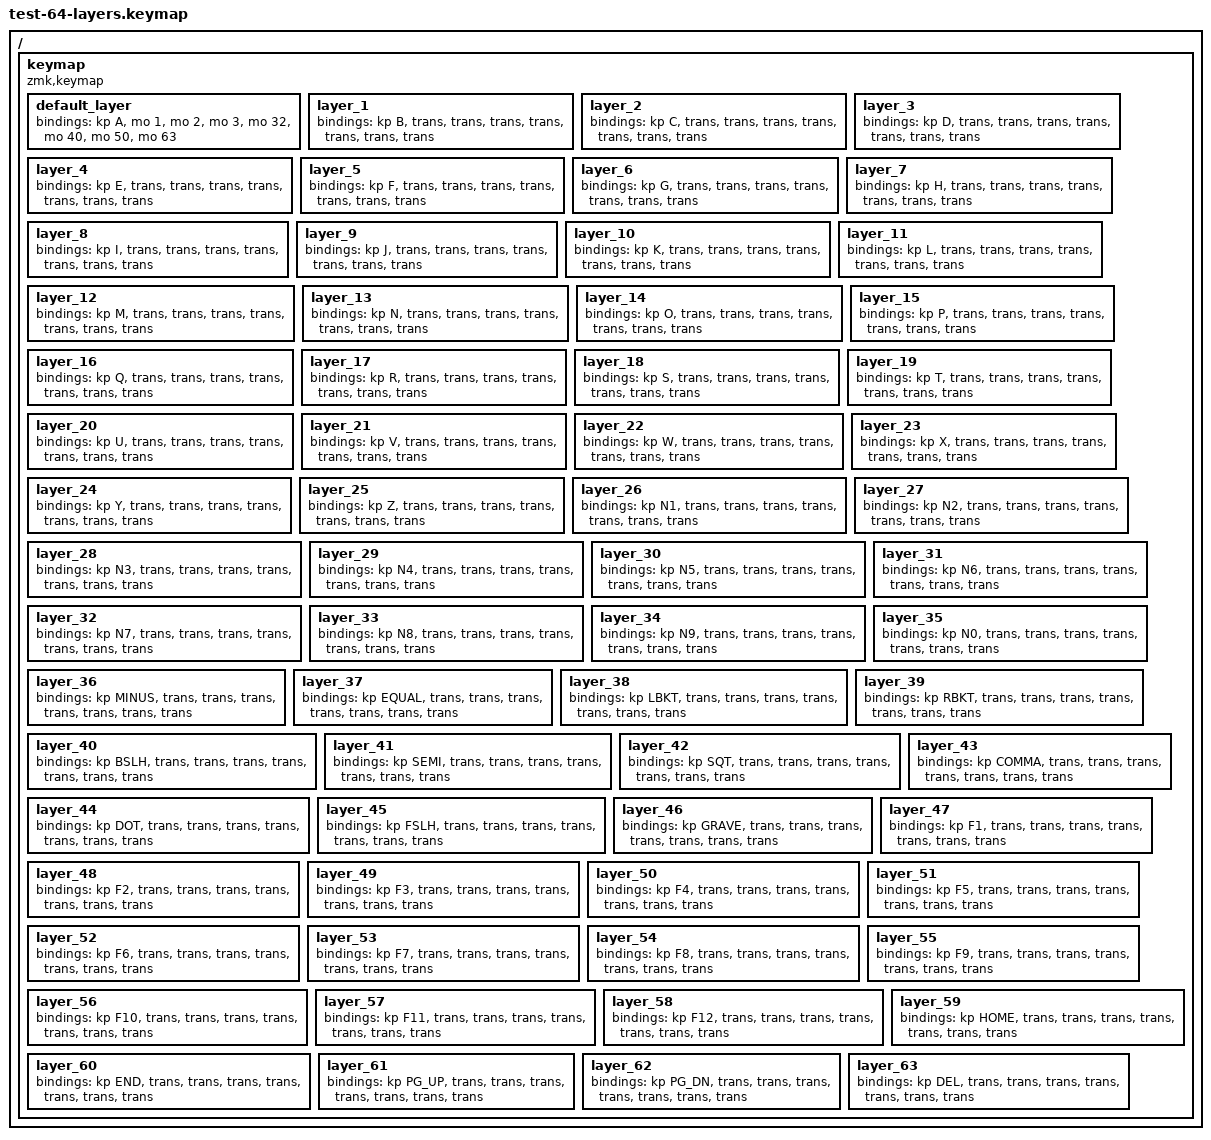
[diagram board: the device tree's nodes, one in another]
/*
 * Test keymap with 64 layers to verify 64-layer support
 * This demonstrates that layers 0-63 can be used
 */

#include <behaviors.dtsi>
#include <dt-bindings/zmk/keys.h>
#include <dt-bindings/zmk/bt.h>

/ {
    keymap {
        compatible = "zmk,keymap";

        // Layer 0-31 (originally supported)
        default_layer { bindings = <&kp A &mo 1 &mo 2 &mo 3 &mo 32 &mo 40 &mo 50 &mo 63>; };
        layer_1 { bindings = <&kp B &trans &trans &trans &trans &trans &trans &trans>; };
        layer_2 { bindings = <&kp C &trans &trans &trans &trans &trans &trans &trans>; };
        layer_3 { bindings = <&kp D &trans &trans &trans &trans &trans &trans &trans>; };
        layer_4 { bindings = <&kp E &trans &trans &trans &trans &trans &trans &trans>; };
        layer_5 { bindings = <&kp F &trans &trans &trans &trans &trans &trans &trans>; };
        layer_6 { bindings = <&kp G &trans &trans &trans &trans &trans &trans &trans>; };
        layer_7 { bindings = <&kp H &trans &trans &trans &trans &trans &trans &trans>; };
        layer_8 { bindings = <&kp I &trans &trans &trans &trans &trans &trans &trans>; };
        layer_9 { bindings = <&kp J &trans &trans &trans &trans &trans &trans &trans>; };
        layer_10 { bindings = <&kp K &trans &trans &trans &trans &trans &trans &trans>; };
        layer_11 { bindings = <&kp L &trans &trans &trans &trans &trans &trans &trans>; };
        layer_12 { bindings = <&kp M &trans &trans &trans &trans &trans &trans &trans>; };
        layer_13 { bindings = <&kp N &trans &trans &trans &trans &trans &trans &trans>; };
        layer_14 { bindings = <&kp O &trans &trans &trans &trans &trans &trans &trans>; };
        layer_15 { bindings = <&kp P &trans &trans &trans &trans &trans &trans &trans>; };
        layer_16 { bindings = <&kp Q &trans &trans &trans &trans &trans &trans &trans>; };
        layer_17 { bindings = <&kp R &trans &trans &trans &trans &trans &trans &trans>; };
        layer_18 { bindings = <&kp S &trans &trans &trans &trans &trans &trans &trans>; };
        layer_19 { bindings = <&kp T &trans &trans &trans &trans &trans &trans &trans>; };
        layer_20 { bindings = <&kp U &trans &trans &trans &trans &trans &trans &trans>; };
        layer_21 { bindings = <&kp V &trans &trans &trans &trans &trans &trans &trans>; };
        layer_22 { bindings = <&kp W &trans &trans &trans &trans &trans &trans &trans>; };
        layer_23 { bindings = <&kp X &trans &trans &trans &trans &trans &trans &trans>; };
        layer_24 { bindings = <&kp Y &trans &trans &trans &trans &trans &trans &trans>; };
        layer_25 { bindings = <&kp Z &trans &trans &trans &trans &trans &trans &trans>; };
        layer_26 { bindings = <&kp N1 &trans &trans &trans &trans &trans &trans &trans>; };
        layer_27 { bindings = <&kp N2 &trans &trans &trans &trans &trans &trans &trans>; };
        layer_28 { bindings = <&kp N3 &trans &trans &trans &trans &trans &trans &trans>; };
        layer_29 { bindings = <&kp N4 &trans &trans &trans &trans &trans &trans &trans>; };
        layer_30 { bindings = <&kp N5 &trans &trans &trans &trans &trans &trans &trans>; };
        layer_31 { bindings = <&kp N6 &trans &trans &trans &trans &trans &trans &trans>; };

        // Layer 32-63 (NEW - only possible with 64-bit support!)
        layer_32 { bindings = <&kp N7 &trans &trans &trans &trans &trans &trans &trans>; };
        layer_33 { bindings = <&kp N8 &trans &trans &trans &trans &trans &trans &trans>; };
        layer_34 { bindings = <&kp N9 &trans &trans &trans &trans &trans &trans &trans>; };
        layer_35 { bindings = <&kp N0 &trans &trans &trans &trans &trans &trans &trans>; };
        layer_36 { bindings = <&kp MINUS &trans &trans &trans &trans &trans &trans &trans>; };
        layer_37 { bindings = <&kp EQUAL &trans &trans &trans &trans &trans &trans &trans>; };
        layer_38 { bindings = <&kp LBKT &trans &trans &trans &trans &trans &trans &trans>; };
        layer_39 { bindings = <&kp RBKT &trans &trans &trans &trans &trans &trans &trans>; };
        layer_40 { bindings = <&kp BSLH &trans &trans &trans &trans &trans &trans &trans>; };
        layer_41 { bindings = <&kp SEMI &trans &trans &trans &trans &trans &trans &trans>; };
        layer_42 { bindings = <&kp SQT &trans &trans &trans &trans &trans &trans &trans>; };
        layer_43 { bindings = <&kp COMMA &trans &trans &trans &trans &trans &trans &trans>; };
        layer_44 { bindings = <&kp DOT &trans &trans &trans &trans &trans &trans &trans>; };
        layer_45 { bindings = <&kp FSLH &trans &trans &trans &trans &trans &trans &trans>; };
        layer_46 { bindings = <&kp GRAVE &trans &trans &trans &trans &trans &trans &trans>; };
        layer_47 { bindings = <&kp F1 &trans &trans &trans &trans &trans &trans &trans>; };
        layer_48 { bindings = <&kp F2 &trans &trans &trans &trans &trans &trans &trans>; };
        layer_49 { bindings = <&kp F3 &trans &trans &trans &trans &trans &trans &trans>; };
        layer_50 { bindings = <&kp F4 &trans &trans &trans &trans &trans &trans &trans>; };
        layer_51 { bindings = <&kp F5 &trans &trans &trans &trans &trans &trans &trans>; };
        layer_52 { bindings = <&kp F6 &trans &trans &trans &trans &trans &trans &trans>; };
        layer_53 { bindings = <&kp F7 &trans &trans &trans &trans &trans &trans &trans>; };
        layer_54 { bindings = <&kp F8 &trans &trans &trans &trans &trans &trans &trans>; };
        layer_55 { bindings = <&kp F9 &trans &trans &trans &trans &trans &trans &trans>; };
        layer_56 { bindings = <&kp F10 &trans &trans &trans &trans &trans &trans &trans>; };
        layer_57 { bindings = <&kp F11 &trans &trans &trans &trans &trans &trans &trans>; };
        layer_58 { bindings = <&kp F12 &trans &trans &trans &trans &trans &trans &trans>; };
        layer_59 { bindings = <&kp HOME &trans &trans &trans &trans &trans &trans &trans>; };
        layer_60 { bindings = <&kp END &trans &trans &trans &trans &trans &trans &trans>; };
        layer_61 { bindings = <&kp PG_UP &trans &trans &trans &trans &trans &trans &trans>; };
        layer_62 { bindings = <&kp PG_DN &trans &trans &trans &trans &trans &trans &trans>; };
        layer_63 { bindings = <&kp DEL &trans &trans &trans &trans &trans &trans &trans>; };
    };
};
